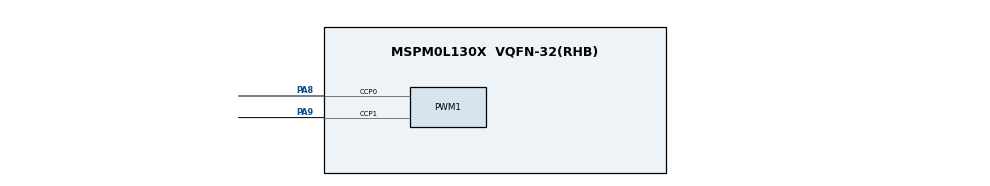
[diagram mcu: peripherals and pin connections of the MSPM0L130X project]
/**
 * @cliArgs --device "MSPM0L130X" --package "VQFN-32(RHB)" --part "Default" --product "mspm0_sdk@1.20.01.06"
 * @versions {"tool":"1.20.0+3587"}
 */

/**
 * Import the modules used in this configuration.
 */
const Board  = scripting.addModule("/ti/driverlib/Board");
const GPIO   = scripting.addModule("/ti/driverlib/GPIO", {}, false);
const GPIO1  = GPIO.addInstance();
const PWM    = scripting.addModule("/ti/driverlib/PWM", {}, false);
const PWM1   = PWM.addInstance();
const SYSCTL = scripting.addModule("/ti/driverlib/SYSCTL");
const TIMER  = scripting.addModule("/ti/driverlib/TIMER", {}, false);
const TIMER1 = TIMER.addInstance();

/**
 * Write custom configuration values to the imported modules.
 */
const gate6  = system.clockTree["MFCLKGATE"];
gate6.enable = true;

const gate7  = system.clockTree["MFPCLKGATE"];
gate7.enable = true;


GPIO1.$name                         = "MATRIX";
GPIO1.associatedPins.create(8);
GPIO1.associatedPins[0].$name       = "V1";
GPIO1.associatedPins[0].assignedPin = "13";
GPIO1.associatedPins[1].$name       = "V2";
GPIO1.associatedPins[1].assignedPin = "14";
GPIO1.associatedPins[2].$name       = "V3";
GPIO1.associatedPins[2].assignedPin = "17";
GPIO1.associatedPins[3].$name       = "V4";
GPIO1.associatedPins[3].assignedPin = "18";
GPIO1.associatedPins[4].$name       = "H1";
GPIO1.associatedPins[4].direction   = "INPUT";
GPIO1.associatedPins[4].assignedPin = "0";
GPIO1.associatedPins[5].$name       = "H2";
GPIO1.associatedPins[5].direction   = "INPUT";
GPIO1.associatedPins[5].assignedPin = "1";
GPIO1.associatedPins[6].$name       = "H3";
GPIO1.associatedPins[6].direction   = "INPUT";
GPIO1.associatedPins[6].assignedPin = "7";
GPIO1.associatedPins[7].$name       = "H4";
GPIO1.associatedPins[7].direction   = "INPUT";
GPIO1.associatedPins[7].assignedPin = "12";

PWM1.$name                      = "PWM_0";
PWM1.clockDivider               = 4;
PWM1.timerCount                 = 200;
PWM1.pwmMode                    = "EDGE_ALIGN_UP";
PWM1.peripheral.ccp0Pin.$assign = "PA8";
PWM1.peripheral.ccp1Pin.$assign = "PA9";
PWM1.PWM_CHANNEL_0.$name        = "ti_driverlib_pwm_PWMTimerCC0";
PWM1.PWM_CHANNEL_0.dutyCycle    = 50;
PWM1.PWM_CHANNEL_1.$name        = "ti_driverlib_pwm_PWMTimerCC1";
PWM1.ccp0PinConfig.$name        = "ti_driverlib_gpio_GPIOPinGeneric0";
PWM1.ccp1PinConfig.$name        = "ti_driverlib_gpio_GPIOPinGeneric1";

SYSCTL.MFCLKEn     = true;
SYSCTL.MFPCLKEn    = true;
SYSCTL.clockTreeEn = true;

TIMER1.$name              = "TIMER_0";
TIMER1.timerClkPrescale   = 100;
TIMER1.timerClkSrc        = "MFCLK";
TIMER1.interrupts         = ["ZERO"];
TIMER1.timerMode          = "PERIODIC";
TIMER1.timerPeriod        = "1s";
TIMER1.peripheral.$assign = "TIMG1";

/**
 * Pinmux solution for unlocked pins/peripherals. This ensures that minor changes to the automatic solver in a future
 * version of the tool will not impact the pinmux you originally saw.  These lines can be completely deleted in order to
 * re-solve from scratch.
 */
Board.peripheral.$suggestSolution            = "DEBUGSS";
Board.peripheral.swclkPin.$suggestSolution   = "PA20";
Board.peripheral.swdioPin.$suggestSolution   = "PA19";
GPIO1.associatedPins[0].pin.$suggestSolution = "PA13";
GPIO1.associatedPins[1].pin.$suggestSolution = "PA14";
GPIO1.associatedPins[2].pin.$suggestSolution = "PA17/OPA1.IN0-";
GPIO1.associatedPins[3].pin.$suggestSolution = "PA18";
GPIO1.associatedPins[4].pin.$suggestSolution = "PA0";
GPIO1.associatedPins[5].pin.$suggestSolution = "PA1";
GPIO1.associatedPins[6].pin.$suggestSolution = "PA7";
GPIO1.associatedPins[7].pin.$suggestSolution = "PA12";
PWM1.peripheral.$suggestSolution             = "TIMG2";
